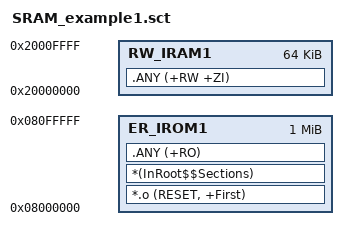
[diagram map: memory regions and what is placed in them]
; *************************************************************
; *** Scatter-Loading Description File generated by uVision ***
; *************************************************************

; 加载域名 (基地址 | ("+" 地址偏移)) [属性列表] [最大容量]  方括号中的为选填内容
LR_IROM1 0x08000000 0x00100000 {        ; 注释: 加载域，基地址 空间大小
    ; 执行区域描述 +

    ; 执行域名 (基地址 | "+" 地址偏移) [属性列表] [最大容量 ]   方括号中的为选填内容
    ER_IROM1 0x08000000 0x00100000 {        ; 注释: 加载地址 = 执行地址
        ; 输入节区描述

        ; 模块选择样式 "(" 输入节区样式 "," "+" 输入节区属性")"
        ; 模块选择样式 "(" 输入节区样式 "," "+" 节区特性")"
        ; 模块选择样式 "(" 输入符号样式 "," "+" 节区特性")"
        ; 模块选择样式 "(" 输入符号样式 "," "+" 输入节区属性")"

        ; 模块选择样式：模块选择样式可用于选择 o 及 lib 目标文件作为输入节区，它可以直接使用目标文件名或“*”通配符，也可以使用“.ANY”。
        ; 输入节区样式：我们知道在目标文件中会包含多个节区或符号，通过输入节区样式可以选择要控制的节区。
        ; 输入符号样式：同样地，使用输入符号样式可以选择要控制的符号，符号样式需要使用“:gdef:”来修饰。例如可以使用“*(:gdef:Value_Test)”来控制选择符号“Value_Test”。
        ; 输入节区属性：通过在模块选择样式后面加入输入节区属性，可以选择样式中不同的内容，每个节区属性描述符前要写一个 “+” 号，使用 空格 或 “，” 号分隔开，可以使用的节区属性描述符。

        ; 示例文件中“(RESET，+First)”语句的 RESET 就是输入节区样式，它选择了名为 RESET 的节区，并使用后面介绍的节区特性控制字“+First”表示它要存储到本区域的第一个地址。
        *.o (RESET, +First)                     ; 使用语句“.o”可以选择所有 o 文件
        ; 示例文件中的“(InRoot$$Sections)”是一个链接器支持的特殊选择符号，它可以选择所有标准库里要求存储到 root 区域的节区，如 __main.o、__scatter.o 等内容。
        *(InRoot$$Sections)
        .ANY (+RO)                              ; 使用 “*” 或 “.ANY” 可以选择所有的 o 文件及 lib 文件
    }

    RW_IRAM1 0x20000000 0x00010000 {    ; 注释: 可读写数据
        .ANY (+RW +ZI)
    }
}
